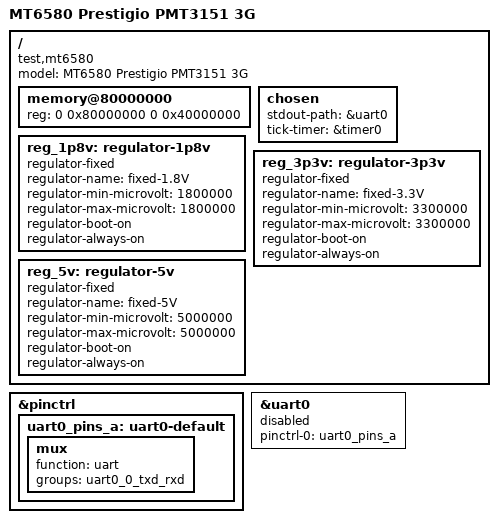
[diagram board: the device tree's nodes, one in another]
/*
 * Copyright (C) 2018 MediaTek Inc.
 * Author: Ryder Lee <ryder.lee@mediatek.com>
 *
 * SPDX-License-Identifier: (GPL-2.0 OR MIT)
 */

/dts-v1/;
#include "mt6580.dtsi"
#include "mt6580-u-boot.dtsi"

/ {
	model = "MT6580 Prestigio PMT3151 3G";
	compatible = "test,mt6580", "mediatek,mt6580";

	memory@80000000 {
		device_type = "memory";
		reg = <0 0x80000000 0 0x40000000>;
	};

	chosen {
		stdout-path = &uart0;
		tick-timer = &timer0;
	};

	reg_1p8v: regulator-1p8v {
		compatible = "regulator-fixed";
		regulator-name = "fixed-1.8V";
		regulator-min-microvolt = <1800000>;
		regulator-max-microvolt = <1800000>;
		regulator-boot-on;
		regulator-always-on;
	};

	reg_3p3v: regulator-3p3v {
		compatible = "regulator-fixed";
		regulator-name = "fixed-3.3V";
		regulator-min-microvolt = <3300000>;
		regulator-max-microvolt = <3300000>;
		regulator-boot-on;
		regulator-always-on;
	};

	reg_5v: regulator-5v {
		compatible = "regulator-fixed";
		regulator-name = "fixed-5V";
		regulator-min-microvolt = <5000000>;
		regulator-max-microvolt = <5000000>;
		regulator-boot-on;
		regulator-always-on;
	};
};

/*&mmc0 {
	pinctrl-names = "default";
	pinctrl-0 = <&mmc0_pins_default>;
	status = "okay";
	bus-width = <8>;
	max-frequency = <50000000>;
	cap-mmc-highspeed;
	vmmc-supply = <&reg_3p3v>;
	vqmmc-supply = <&reg_1p8v>;
	non-removable;
};

&mmc1 {
	pinctrl-names = "default";
	pinctrl-0 = <&mmc1_pins_default>;
	status = "okay";
	bus-width = <4>;
	max-frequency = <50000000>;
	cap-sd-highspeed;
	r_smpl = <1>;
	vmmc-supply = <&reg_3p3v>;
	vqmmc-supply = <&reg_3p3v>;
};*/

&pinctrl {
    uart0_pins_a: uart0-default {
		mux {
			function = "uart";
			groups =  "uart0_0_txd_rxd";
		};
	};
};


&uart0 {
	pinctrl-names = "default";
	pinctrl-0 = <&uart0_pins_a>;
	status = "disabled";
};
